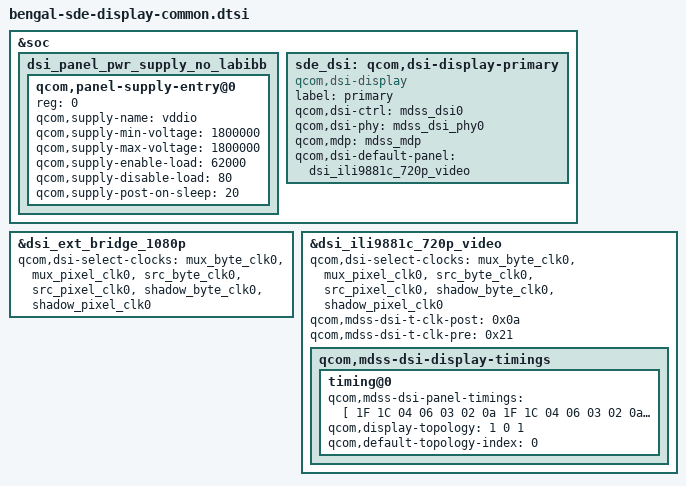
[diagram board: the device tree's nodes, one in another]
#include "dsi-panel-ext-bridge-1080p.dtsi"
#include "dsi-panel-ili988c-dual-video.dtsi"
#include <dt-bindings/clock/mdss-14nm-pll-clk.h>

&soc {
	dsi_panel_pwr_supply_no_labibb: dsi_panel_pwr_supply_no_labibb {
		#address-cells = <1>;
		#size-cells = <0>;

		qcom,panel-supply-entry@0 {
			reg = <0>;
			qcom,supply-name = "vddio";
			qcom,supply-min-voltage = <1800000>;
			qcom,supply-max-voltage = <1800000>;
			qcom,supply-enable-load = <62000>;
			qcom,supply-disable-load = <80>;
			qcom,supply-post-on-sleep = <20>;
		};
	};

	sde_dsi: qcom,dsi-display-primary {
		compatible = "qcom,dsi-display";
		label = "primary";

		qcom,dsi-ctrl = <&mdss_dsi0>;
		qcom,dsi-phy = <&mdss_dsi_phy0>;

		qcom,mdp = <&mdss_mdp>;
		qcom,dsi-default-panel = <&dsi_ili9881c_720p_video>;
	};
};

&dsi_ext_bridge_1080p {
	qcom,dsi-select-clocks = "mux_byte_clk0", "mux_pixel_clk0",
		"src_byte_clk0", "src_pixel_clk0",
		"shadow_byte_clk0", "shadow_pixel_clk0";
};

&dsi_ili9881c_720p_video {
	qcom,dsi-select-clocks = "mux_byte_clk0", "mux_pixel_clk0",
		"src_byte_clk0", "src_pixel_clk0",
		"shadow_byte_clk0", "shadow_pixel_clk0";
	qcom,mdss-dsi-t-clk-post = <0x0a>;
	qcom,mdss-dsi-t-clk-pre = <0x21>;
	qcom,mdss-dsi-display-timings {
		timing@0 {
			qcom,mdss-dsi-panel-timings = [
				1F 1C 04 06 03 02 0a
				1F 1C 04 06 03 02 0a
				1F 1C 04 06 03 02 0a
				1F 1C 04 06 03 02 0a
				1F 10 04 06 03 02 0a
			];
			qcom,display-topology = <1 0 1>;
			qcom,default-topology-index = <0>;
		};
	};
};
